VERSION ""

NS_ :

BS_:

BU_:
VAL_TABLE_ head_light 0 "off" 2 "parking" 3 "way" 1 "auto" ;
VAL_TABLE_ transmission__selctor 1 "P" 4 "D" 3 "N" 2 "R" ;
VAL_TABLE_ Charger_status 32 "Charger active" 33 "charger dis active" 1 "not connect " ;

BO_ 1344 HS_CAN__540: 3 Vector__XXX
 SG_ Odometer : 7|24@0+ (1,0) [0|16777215] "" Vector__XXX

BO_ 175 HS_CAN__AF: 4 Vector__XXX
 SG_ Brake__Pedal : 31|1@0+ (1,0) [0|1] "" Vector__XXX
 SG_ Accelertion_Pedal_Position : 7|8@0+ (0.393,0) [0|255] "" Vector__XXX

BO_ 1146 HS_CAN__47A: 1 Vector__XXX
 SG_ head_light : 6|2@0+ (1,0) [0|3] "" Vector__XXX

BO_ 865 HS_CAN__361: 6 Vector__XXX
 SG_ A_C : 43|1@0+ (1,0) [0|1] "" Vector__XXX

BO_ 404 HS_CAN__194: 4 Vector__XXX
 SG_ transmission__selctor : 26|3@0+ (1,0) [0|4] "" Vector__XXX

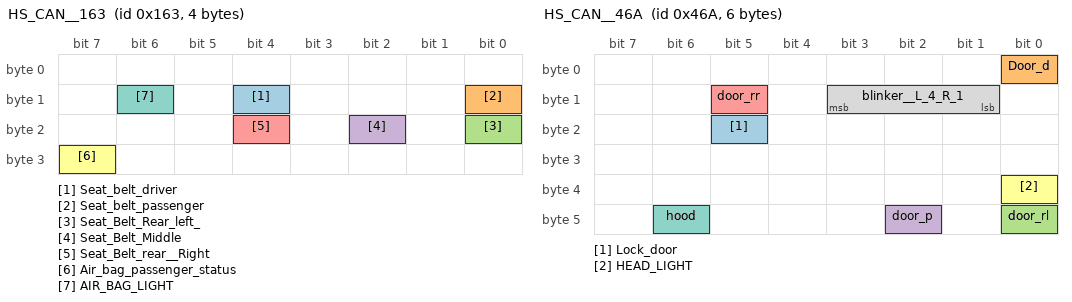
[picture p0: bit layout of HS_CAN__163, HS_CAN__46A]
BO_ 355 HS_CAN__163: 4 Vector__XXX
 SG_ Seat_belt_driver : 12|1@0+ (1,0) [0|1] "" Vector__XXX
 SG_ Seat_belt_passenger : 8|1@0+ (1,0) [0|1] "" Vector__XXX
 SG_ Seat_Belt_Rear_left_ : 16|1@0+ (1,0) [0|1] "" Vector__XXX
 SG_ Seat_Belt_Middle : 18|1@0+ (1,0) [0|1] "" Vector__XXX
 SG_ Seat_Belt_rear__Right : 20|1@0+ (1,0) [0|1] "" Vector__XXX
 SG_ Air_bag_passenger_status : 31|1@0+ (1,0) [0|1] "" Vector__XXX
 SG_ AIR_BAG_LIGHT : 14|1@0+ (1,0) [0|1] "" Vector__XXX

BO_ 674 HS_CAN__2A2: 8 Vector__XXX
 SG_ RANGE_TO_EMPTY : 55|16@0+ (1,0) [0|65535] "KM" Vector__XXX
 SG_ Charger_status : 23|8@0+ (1,0) [0|33] "" Vector__XXX

BO_ 359 HS_CAN__167: 4 Vector__XXX
 SG_ Drill_down : 28|1@0+ (1,0) [0|1] "" Vector__XXX

BO_ 582 HS_CAN__246: 5 Vector__XXX
 SG_ ESP : 37|1@0+ (1,0) [0|1] "" Vector__XXX

BO_ 851 HS_CAN__353: 6 Vector__XXX
 SG_ vss : 39|16@0+ (0.015,0) [0|65535] "" Vector__XXX

BO_ 148 HS_CAN__94: 7 Vector__XXX
 SG_ Motor_speed : 3|12@0+ (10,0) [0|40950] "" Vector__XXX
 SG_ PARKING_BRAKES : 48|1@0+ (1,0) [0|1] "" Vector__XXX

BO_ 667 HS_CAN__29B: 1 Vector__XXX
 SG_ CABLE_STATUS_0_CONNECT : 6|1@0+ (1,0) [0|1] "" Vector__XXX

BO_ 1130 HS_CAN__46A: 6 Vector__XXX
 SG_ Lock_door : 21|1@0+ (1,0) [0|1] "" Vector__XXX
 SG_ Door_d : 0|1@0+ (1,0) [0|1] "" Vector__XXX
 SG_ door_rl : 40|1@0+ (1,0) [0|1] "" Vector__XXX
 SG_ door_p : 42|1@0+ (1,0) [0|1] "" Vector__XXX
 SG_ door_rr : 13|1@0+ (1,0) [0|1] "" Vector__XXX
 SG_ HEAD_LIGHT : 32|1@0+ (1,0) [0|1] "" Vector__XXX
 SG_ hood : 46|1@0+ (1,0) [0|1] "" Vector__XXX
 SG_ blinker__L_4_R_1 : 11|3@0+ (1,0) [0|7] "" Vector__XXX

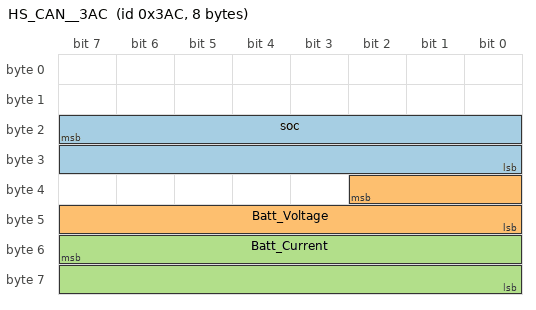
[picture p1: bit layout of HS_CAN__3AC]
BO_ 940 HS_CAN__3AC: 8 Vector__XXX
 SG_ soc : 23|16@0+ (0.1,0) [0|65535] "%" Vector__XXX
 SG_ Batt_Voltage : 34|11@0+ (0.25,0) [0|511.75] "" Vector__XXX
 SG_ Batt_Current : 55|16@0+ (0.05,-1000) [0|65535] "" Vector__XXX

BO_ 936 HS_CAN__3A8: 5 Vector__XXX
 SG_ Time_to_charging_ : 31|10@0+ (1,0) [0|1023] "min" Vector__XXX

BA_DEF_ SG_  "SignalType" STRING ;
BA_DEF_DEF_  "SignalType" "";
BA_ "SignalType" SG_ 1146 head_light "ENM";
BA_ "SignalType" SG_ 404 transmission__selctor "ENM";
BA_ "SignalType" SG_ 674 Charger_status "ENM";
VAL_ 1146 head_light 0 "off" 2 "parking" 3 "way" 1 "auto" ;
VAL_ 404 transmission__selctor 1 "P" 4 "D" 3 "N" 2 "R" ;
VAL_ 674 Charger_status 32 "Charger active" 33 "charger dis active" 1 "not connect " ;
